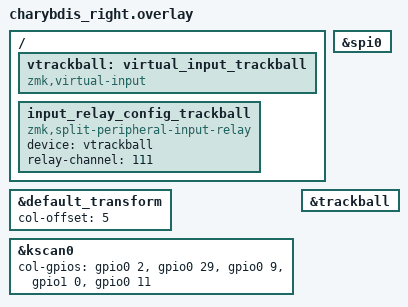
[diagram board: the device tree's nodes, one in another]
#include "charybdis.dtsi"
#include "charybdis_pmw3610.dtsi"

// The matrix transform is 6 columns over because the left half is 6 columns wide.
&default_transform {
	col-offset = <5>;
};

&kscan0 {
	col-gpios
        = <&gpio0 2 (GPIO_ACTIVE_HIGH | GPIO_PULL_DOWN)>
        , <&gpio0 29 (GPIO_ACTIVE_HIGH | GPIO_PULL_DOWN)>
        , <&gpio0 9 (GPIO_ACTIVE_HIGH | GPIO_PULL_DOWN)>
        , <&gpio1 0  (GPIO_ACTIVE_HIGH | GPIO_PULL_DOWN)>
        , <&gpio0 11 (GPIO_ACTIVE_HIGH | GPIO_PULL_DOWN)>
		;
};

&spi0 {
    status = "okay";
};

&trackball {
    status = "okay";
};

/ {
	vtrackball: virtual_input_trackball {
		compatible = "zmk,virtual-input";
	};

	input_relay_config_trackball {
		compatible = "zmk,split-peripheral-input-relay";
		device = <&vtrackball>;
		relay-channel = <111>;
	};
};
